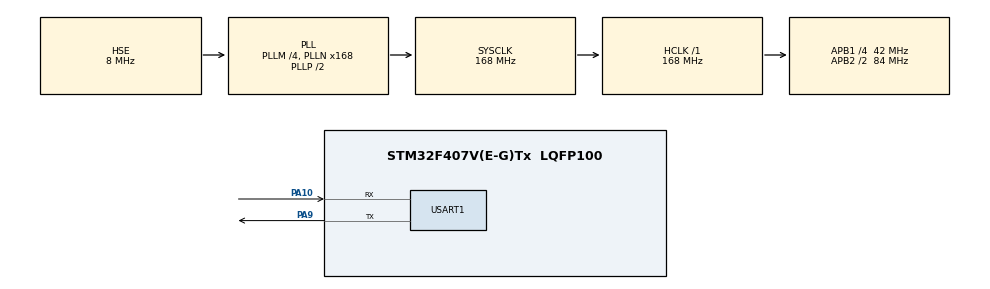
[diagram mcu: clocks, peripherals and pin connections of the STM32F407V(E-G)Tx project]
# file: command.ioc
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ADC1.Channel-3\#ChannelRegularConversion=ADC_CHANNEL_TEMPSENSOR
ADC1.NbrOfConversionFlag=1
ADC1.Rank-3\#ChannelRegularConversion=1
ADC1.SamplingTime-3\#ChannelRegularConversion=ADC_SAMPLETIME_480CYCLES
ADC1.master=1
Dma.Request0=USART1_RX
Dma.USART1_RX.0.Direction=DMA_PERIPH_TO_MEMORY
Dma.USART1_RX.0.FIFOMode=DMA_FIFOMODE_DISABLE
Dma.USART1_RX.0.Instance=DMA2_Stream2
Dma.USART1_RX.0.MemDataAlignment=DMA_MDATAALIGN_BYTE
Dma.USART1_RX.0.MemInc=DMA_MINC_ENABLE
Dma.USART1_RX.0.Mode=DMA_CIRCULAR
Dma.USART1_RX.0.PeriphDataAlignment=DMA_PDATAALIGN_BYTE
Dma.USART1_RX.0.PeriphInc=DMA_PINC_DISABLE
Dma.USART1_RX.0.Priority=DMA_PRIORITY_MEDIUM
FREERTOS.Tasks01=defaultTask,24,128,StartDefaultTask,Default,NULL,Dynamic,NULL,NULL
Mcu.Family=STM32F4
Mcu.Name=STM32F407V(E-G)Tx
Mcu.Package=LQFP100
NVIC.DMA2_Stream2_IRQn=true\:5\:0\:false\:false\:true\:true\:false\:true\:true
NVIC.PriorityGroup=NVIC_PRIORITYGROUP_4
NVIC.TIM6_DAC_IRQn=true\:15\:0\:false\:false\:true\:false\:false\:true\:true
NVIC.TimeBase=TIM6_DAC_IRQn
NVIC.TimeBaseIP=TIM6
PA10.Mode=Asynchronous
PA10.Signal=USART1_RX
PA13.Mode=Serial_Wire
PA13.Signal=SYS_JTMS-SWDIO
PA14.Mode=Serial_Wire
PA14.Signal=SYS_JTCK-SWCLK
PA9.Mode=Asynchronous
PA9.Signal=USART1_TX
PH0-OSC_IN.Mode=HSE-External-Oscillator
PH0-OSC_IN.Signal=RCC_OSC_IN
PH1-OSC_OUT.Mode=HSE-External-Oscillator
PH1-OSC_OUT.Signal=RCC_OSC_OUT
ProjectManager.HeapSize=0x200
ProjectManager.StackSize=0x400
ProjectManager.TargetToolchain=MDK-ARM V5.32
RCC.48MHZClocksFreq_Value=84000000
RCC.AHBFreq_Value=168000000
RCC.APB1CLKDivider=RCC_HCLK_DIV4
RCC.APB1Freq_Value=42000000
RCC.APB1TimFreq_Value=84000000
RCC.APB2CLKDivider=RCC_HCLK_DIV2
RCC.APB2Freq_Value=84000000
RCC.APB2TimFreq_Value=168000000
RCC.CortexFreq_Value=168000000
RCC.HCLKFreq_Value=168000000
RCC.HSE_VALUE=8000000
RCC.HSI_VALUE=16000000
RCC.LSE_VALUE=32768
RCC.PLLM=4
RCC.PLLN=168
RCC.PLLSourceVirtual=RCC_PLLSOURCE_HSE
RCC.SYSCLKFreq_VALUE=168000000
RCC.SYSCLKSource=RCC_SYSCLKSOURCE_PLLCLK
RCC.VCOOutputFreq_Value=336000000
USART1.VirtualMode=VM_ASYNC
VP_ADC1_TempSens_Input.Mode=IN-TempSens
VP_FREERTOS_VS_CMSIS_V2.Mode=CMSIS_V2
VP_SYS_VS_tim6.Mode=TIM6
board=custom

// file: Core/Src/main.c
/* USER CODE BEGIN Header */
/**
  ******************************************************************************
  * @file           : main.c
  * @brief          : Main program body
  ******************************************************************************
  * @attention
  *
  * Copyright (c) 2026 STMicroelectronics.
  * All rights reserved.
  *
  * This software is licensed under terms that can be found in the LICENSE file
  * in the root directory of this software component.
  * If no LICENSE file comes with this software, it is provided AS-IS.
  *
  ******************************************************************************
  */
/* USER CODE END Header */
#include "main.h"
#include "cmsis_os.h"
#include "adc.h"
#include "dma.h"
#include "usart.h"
#include "gpio.h"

void SystemClock_Config(void);
void MX_FREERTOS_Init(void);

int main(void)
{

  /* MCU Configuration--------------------------------------------------------*/

  /* Reset of all peripherals, Initializes the Flash interface and the Systick. */
  HAL_Init();

  /* Configure the system clock */
  SystemClock_Config();

  /* Initialize all configured peripherals */
  MX_GPIO_Init();
  MX_DMA_Init();
  MX_USART1_UART_Init();
  MX_ADC1_Init();

  /* Init scheduler */
  osKernelInitialize();  /* Call init function for freertos objects (in cmsis_os2.c) */
  MX_FREERTOS_Init();

  /* Start scheduler */
  osKernelStart();

  /* We should never get here as control is now taken by the scheduler */

  /* Infinite loop */
  while (1)
  {

  }
}

void SystemClock_Config(void)
{
  RCC_OscInitTypeDef RCC_OscInitStruct = {0};
  RCC_ClkInitTypeDef RCC_ClkInitStruct = {0};

  /** Configure the main internal regulator output voltage
  */
  __HAL_RCC_PWR_CLK_ENABLE();
  __HAL_PWR_VOLTAGESCALING_CONFIG(PWR_REGULATOR_VOLTAGE_SCALE1);

  /** Initializes the RCC Oscillators according to the specified parameters
  * in the RCC_OscInitTypeDef structure.
  */
  RCC_OscInitStruct.OscillatorType = RCC_OSCILLATORTYPE_HSE;
  RCC_OscInitStruct.HSEState = RCC_HSE_ON;
  RCC_OscInitStruct.PLL.PLLState = RCC_PLL_ON;
  RCC_OscInitStruct.PLL.PLLSource = RCC_PLLSOURCE_HSE;
  RCC_OscInitStruct.PLL.PLLM = 4;
  RCC_OscInitStruct.PLL.PLLN = 168;
  RCC_OscInitStruct.PLL.PLLP = RCC_PLLP_DIV2;
  RCC_OscInitStruct.PLL.PLLQ = 4;
  if (HAL_RCC_OscConfig(&RCC_OscInitStruct) != HAL_OK)
  {
    Error_Handler();
  }

  /** Initializes the CPU, AHB and APB buses clocks
  */
  RCC_ClkInitStruct.ClockType = RCC_CLOCKTYPE_HCLK|RCC_CLOCKTYPE_SYSCLK
                              |RCC_CLOCKTYPE_PCLK1|RCC_CLOCKTYPE_PCLK2;
  RCC_ClkInitStruct.SYSCLKSource = RCC_SYSCLKSOURCE_PLLCLK;
  RCC_ClkInitStruct.AHBCLKDivider = RCC_SYSCLK_DIV1;
  RCC_ClkInitStruct.APB1CLKDivider = RCC_HCLK_DIV4;
  RCC_ClkInitStruct.APB2CLKDivider = RCC_HCLK_DIV2;

  if (HAL_RCC_ClockConfig(&RCC_ClkInitStruct, FLASH_LATENCY_5) != HAL_OK)
  {
    Error_Handler();
  }
}

void HAL_TIM_PeriodElapsedCallback(TIM_HandleTypeDef *htim)
{
  if (htim->Instance == TIM6)
  {
    HAL_IncTick();
  }
}

void Error_Handler(void)
{
  __disable_irq();
  while (1)
  {
  }
}

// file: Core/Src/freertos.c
/* USER CODE BEGIN Header */
/**
  ******************************************************************************
  * File Name          : freertos.c
  * Description        : Code for freertos applications
  ******************************************************************************
  * @attention
  *
  * Copyright (c) 2026 STMicroelectronics.
  * All rights reserved.
  *
  * This software is licensed under terms that can be found in the LICENSE file
  * in the root directory of this software component.
  * If no LICENSE file comes with this software, it is provided AS-IS.
  *
  ******************************************************************************
  */
/* USER CODE END Header */

#include "FreeRTOS.h"
#include "task.h"
#include "main.h"
#include "cmsis_os.h"

/* USER CODE BEGIN Includes */
#include "app_ipc.h"
#include "led_task.h"        /* 1Hz 闪灯任务: 当前停用, 保留以便随时恢复 */
#include "print_task.h"
#include "adc_task.h"
#include "btn_led_task.h"
#include "oled_task.h"
#include "uart_cmd_task.h"
/* USER CODE END Includes */

/* Definitions for defaultTask */
osThreadId_t defaultTaskHandle;
const osThreadAttr_t defaultTask_attributes = {
  .name = "defaultTask",
  .stack_size = 128 * 4,
  .priority = (osPriority_t) osPriorityNormal,
};

void StartDefaultTask(void *argument);

void MX_FREERTOS_Init(void); /* (MISRA C 2004 rule 8.1) */

void MX_FREERTOS_Init(void) {

  /* USER CODE BEGIN RTOS_QUEUES */
  /* add queues, ... */
  AppIpc_Init();       /* 创建任务间通信对象 (温度队列 + 温度最新值通道), 必须在任务创建之前 */
  UartCmd_Init();      /* 创建命令通道对象 (接收字节流缓冲 + 发送互斥量), 同样要在任务之前 */
  /* USER CODE END RTOS_QUEUES */

  /* Create the thread(s) */
  /* creation of defaultTask */
  defaultTaskHandle = osThreadNew(StartDefaultTask, NULL, &defaultTask_attributes);

  /* USER CODE BEGIN RTOS_THREADS */
  /* add threads, ... */
  /* LedTask_Create(); */    /* 1Hz 闪灯(LED1): 与按键控制 LED1 冲突, 已停用; 恢复时取消本行注释 */
//PrintTask_Create();        /* 串口打印: 消费温度队列 (USART1) */
  AdcTask_Create();          /* ADC1 内部温度传感器采集 -> 队列 */
  BtnLedTask_Create();       /* 按键事件组控制 LED1/LED2 */
  OledTask_Create();         /* SSD1315 OLED: 20Hz 显示 ADC 内部温度 */
  UartCmd_TaskCreate();      /* 上位机命令: USART1 IDLE+DMA 接收 + 行解析 + 命令分发 */
  /* USER CODE END RTOS_THREADS */

}

void StartDefaultTask(void *argument)
{
  for(;;)
  {
    osDelay(1);
  }
}
